# STM32U585 register map
File version: 2.2
CPU: CM33 r0p1, little endian, MPU, FPU, 4 interrupt priority bits
Registers are 32-bit, read-write, reset 0x0 unless marked. A register's access mark holds for its fields unless they carry their own. Offsets are from the block's base; [hi:lo] are bit positions; {n}, {i} and the like mark numbered series.

## RAMCFG
Base 0x40026000
Same registers: SEC_RAMCFG 0x50026000
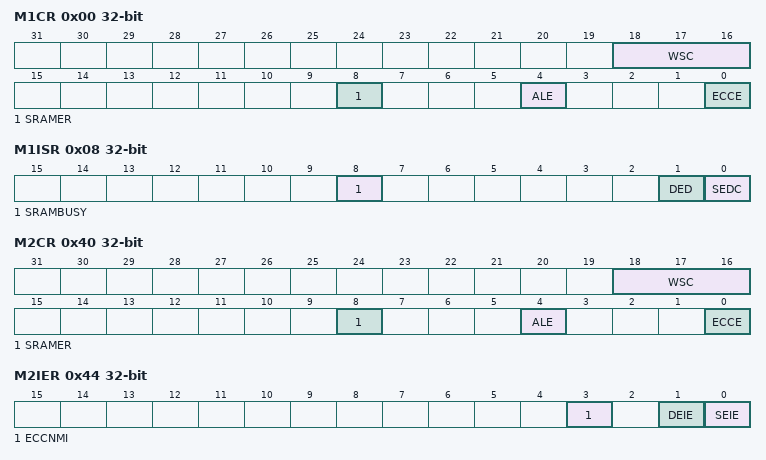
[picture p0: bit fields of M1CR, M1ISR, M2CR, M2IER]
0x00 M1CR — RAMCFG SRAM x control register
  [18:16] WSC, [8] SRAMER, [4] ALE, [0] ECCE
0x08 M1ISR ro — RAMCFG RAMx interrupt status register
  [8] SRAMBUSY, [1] DED, [0] SEDC
0x28 M1ERKEYR wo — RAMCFG SRAM x erase key register
  [7:0] ERASEKEY
0x40 M2CR — RAMCFG SRAM x control register
  [18:16] WSC, [8] SRAMER, [4] ALE, [0] ECCE
0x44 M2IER — RAMCFG SRAM x interrupt enable register
  [3] ECCNMI, [1] DEIE, [0] SEIE
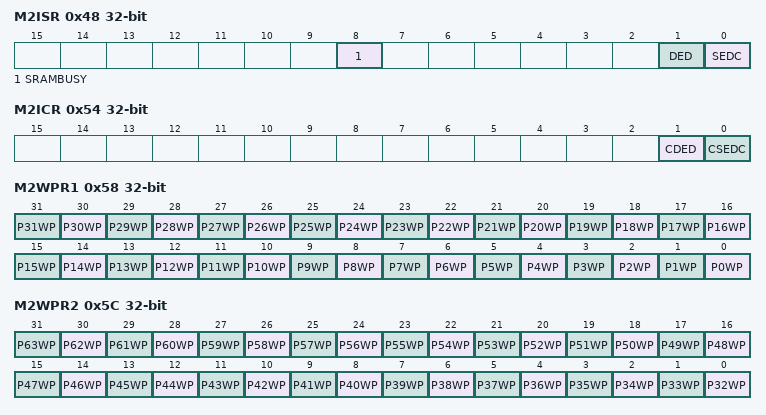
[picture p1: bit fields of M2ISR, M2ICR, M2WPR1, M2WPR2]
0x48 M2ISR ro — RAMCFG RAMx interrupt status register
  [8] SRAMBUSY, [1] DED, [0] SEDC
0x4C M2SEAR ro — RAMCFG RAM x ECC single error address register
  [31:0] ESEA
0x50 M2DEAR ro — RAMCFG RAM x ECC double error address register
  [31:0] EDEA
0x54 M2ICR — RAMCFG RAM x interrupt clear register x
  [1] CDED, [0] CSEDC
0x58 M2WPR1 — RAMCFG SRAM2 write protection register 1
  [n] P{n}WP (n=0..31)
0x5C M2WPR2 — RAMCFG SRAM2 write protection register 2
  [n-32] P{n}WP (n=32..63)
0x64 M2ECCKEYR wo — RAMCFG SRAM x ECC key register
  [7:0] ECCKEY
0x68 M2ERKEYR wo — RAMCFG SRAM x erase key register
  [7:0] ERASEKEY
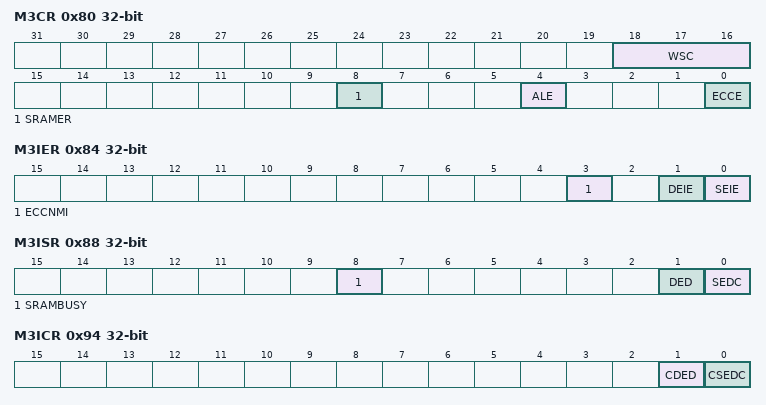
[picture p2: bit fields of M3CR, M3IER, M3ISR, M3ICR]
0x80 M3CR — RAMCFG SRAM x control register
  [18:16] WSC, [8] SRAMER, [4] ALE, [0] ECCE
0x84 M3IER — RAMCFG SRAM x interrupt enable register
  [3] ECCNMI, [1] DEIE, [0] SEIE
0x88 M3ISR ro — RAMCFG RAMx interrupt status register
  [8] SRAMBUSY, [1] DED, [0] SEDC
0x8C M3SEAR ro — RAMCFG RAM x ECC single error address register
  [31:0] ESEA
0x90 M3DEAR ro — RAMCFG RAM x ECC double error address register
  [31:0] EDEA
0x94 M3ICR — RAMCFG RAM x interrupt clear register x
  [1] CDED, [0] CSEDC
0xA4 M3ECCKEYR wo — RAMCFG SRAM x ECC key register
  [7:0] ECCKEY
0xA8 M3ERKEYR wo — RAMCFG SRAM x erase key register
  [7:0] ERASEKEY
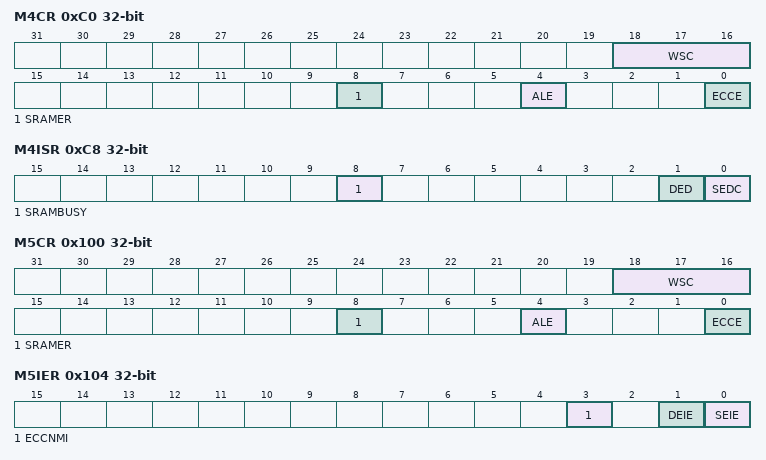
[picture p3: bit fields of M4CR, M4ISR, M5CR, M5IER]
0xC0 M4CR — RAMCFG SRAM x control register
  [18:16] WSC, [8] SRAMER, [4] ALE, [0] ECCE
0xC8 M4ISR ro — RAMCFG RAMx interrupt status register
  [8] SRAMBUSY, [1] DED, [0] SEDC
0xE8 M4ERKEYR wo — RAMCFG SRAM x erase key register
  [7:0] ERASEKEY
0x100 M5CR — RAMCFG SRAM x control register
  [18:16] WSC, [8] SRAMER, [4] ALE, [0] ECCE
0x104 M5IER — RAMCFG SRAM x interrupt enable register
  [3] ECCNMI, [1] DEIE, [0] SEIE
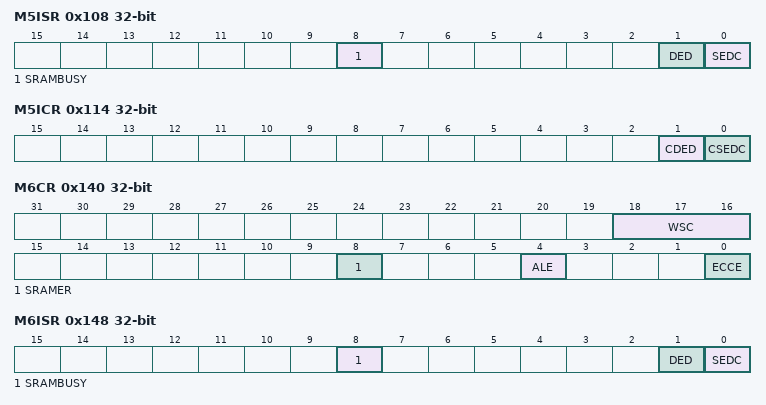
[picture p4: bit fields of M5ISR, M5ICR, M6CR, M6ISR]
0x108 M5ISR ro — RAMCFG RAMx interrupt status register
  [8] SRAMBUSY, [1] DED, [0] SEDC
0x10C M5SEAR ro — RAMCFG RAM x ECC single error address register
  [31:0] ESEA
0x110 M5DEAR ro — RAMCFG RAM x ECC double error address register
  [31:0] EDEA
0x114 M5ICR — RAMCFG RAM x interrupt clear register x
  [1] CDED, [0] CSEDC
0x124 M5ECCKEYR — RAMCFG RAM 5 interrupt clear register x
  [7:0] ECCKEY
0x128 M5ERKEYR — RAMCFG memory 5 erase key register
  [7:0] ERASEKEY wo — Erase write protection key
0x140 M6CR — memory x control register
  [18:16] WSC, [8] SRAMER, [4] ALE, [0] ECCE
0x148 M6ISR ro — RAMCFG memory interrupt status register
  [8] SRAMBUSY — SRAM busy with erase operation
    0=No erase operation on going; 1=Erase operation on going
  [1] DED — ECC double error detected
    0=No double error; 1=Double error detected
  [0] SEDC — ECC single error detected and corrected
    0=No single error; 1=Single error detected and corrected
0x168 M6ERKEYR — RAMCFG memory 6 erase key register
  [7:0] ERASEKEY wo — Erase write protection key

## DCMI — Digital camera interface
Base 0x4202C000
Same registers: SEC_DCMI 0x5202C000
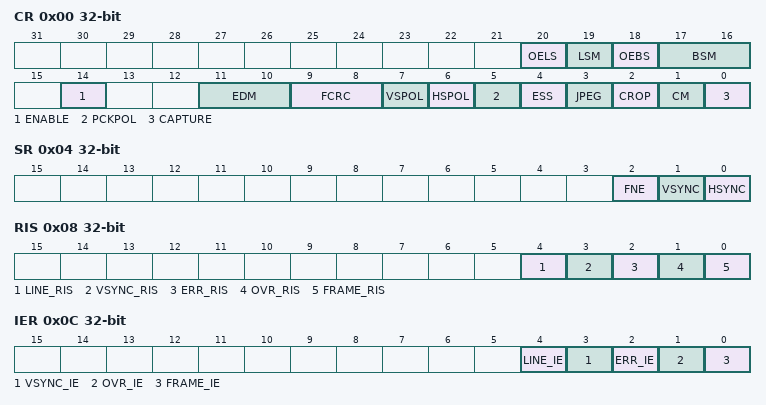
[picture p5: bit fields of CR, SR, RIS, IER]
0x00 CR — control register
  [20] OELS — Odd/Even Line Select (Line Select Start)
  [19] LSM — Line Select mode
  [18] OEBS — Odd/Even Byte Select (Byte Select Start)
  [17:16] BSM — Byte Select mode
  [14] ENABLE — DCMI enable
  [11:10] EDM — Extended data mode
  [9:8] FCRC — Frame capture rate control
  [7] VSPOL — Vertical synchronization polarity
  [6] HSPOL — Horizontal synchronization polarity
  [5] PCKPOL — Pixel clock polarity
  [4] ESS — Embedded synchronization select
  [3] JPEG — JPEG format
  [2] CROP — Crop feature
  [1] CM — Capture mode
  [0] CAPTURE — Capture enable
0x04 SR ro — status register
  [2] FNE — FIFO not empty
  [1] VSYNC — Vertical synchronization
  [0] HSYNC — Horizontal synchronization
0x08 RIS ro — raw interrupt status register
  [4] LINE_RIS — Line raw interrupt status
  [3] VSYNC_RIS — DCMI_VSYNC raw interrupt status
  [2] ERR_RIS — Synchronization error raw interrupt status
  [1] OVR_RIS — Overrun raw interrupt status
  [0] FRAME_RIS — Capture complete raw interrupt status
0x0C IER — interrupt enable register
  [4] LINE_IE — Line interrupt enable
  [3] VSYNC_IE — DCMI_VSYNC interrupt enable
  [2] ERR_IE — Synchronization error interrupt enable
  [1] OVR_IE — Overrun interrupt enable
  [0] FRAME_IE — Capture complete interrupt enable
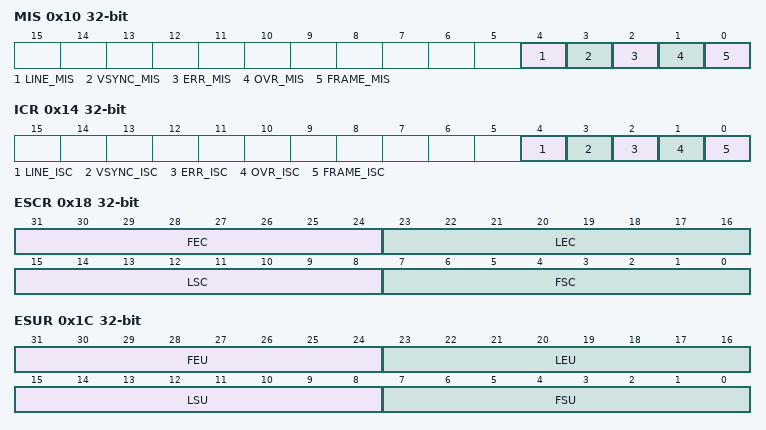
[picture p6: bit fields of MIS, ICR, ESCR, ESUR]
0x10 MIS ro — masked interrupt status register
  [4] LINE_MIS — Line masked interrupt status
  [3] VSYNC_MIS — VSYNC masked interrupt status
  [2] ERR_MIS — Synchronization error masked interrupt status
  [1] OVR_MIS — Overrun masked interrupt status
  [0] FRAME_MIS — Capture complete masked interrupt status
0x14 ICR wo — interrupt clear register
  [4] LINE_ISC — line interrupt status clear
  [3] VSYNC_ISC — Vertical Synchronization interrupt status clear
  [2] ERR_ISC — Synchronization error interrupt status clear
  [1] OVR_ISC — Overrun interrupt status clear
  [0] FRAME_ISC — Capture complete interrupt status clear
0x18 ESCR — background offset register
  [31:24] FEC — Frame end delimiter code
  [23:16] LEC — Line end delimiter code
  [15:8] LSC — Line start delimiter code
  [7:0] FSC — Frame start delimiter code
0x1C ESUR — embedded synchronization unmask register
  [31:24] FEU — Frame end delimiter unmask
  [23:16] LEU — Line end delimiter unmask
  [15:8] LSU — Line start delimiter unmask
  [7:0] FSU — Frame start delimiter unmask
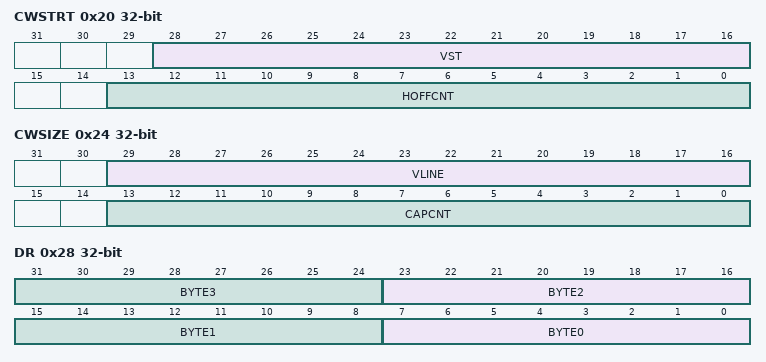
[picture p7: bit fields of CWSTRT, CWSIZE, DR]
0x20 CWSTRT — crop window start
  [28:16] VST — Vertical start line count
  [13:0] HOFFCNT — Horizontal offset count
0x24 CWSIZE — crop window size
  [29:16] VLINE — Vertical line count
  [13:0] CAPCNT — Capture count
0x28 DR ro — data register
  [8n+7:8n] BYTE{n} (n=0..3) — Data byte {n}

## DCB — Debug Control Block
Base 0xE000EE08
0x00 DSCSR — Debug Security Control and Status Register
  [16] CDS — Current domain Secure
